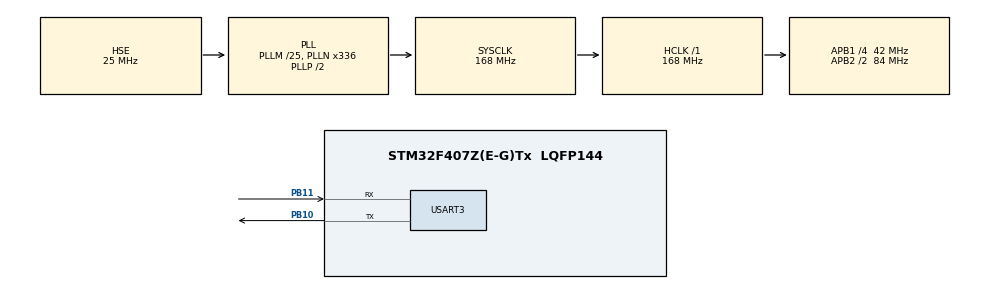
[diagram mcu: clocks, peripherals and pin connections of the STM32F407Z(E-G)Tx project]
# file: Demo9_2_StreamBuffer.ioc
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FREERTOS.Tasks01=Task_Show,24,256,AppTask_Show,Default,NULL,Dynamic,NULL,NULL
FREERTOS.configUSE_NEWLIB_REENTRANT=1
Mcu.Family=STM32F4
Mcu.Name=STM32F407Z(E-G)Tx
Mcu.Package=LQFP144
NVIC.PriorityGroup=NVIC_PRIORITYGROUP_4
NVIC.RTC_WKUP_IRQn=true\:5\:0\:false\:false\:true\:true\:true\:true\:true
NVIC.TIM6_DAC_IRQn=true\:0\:0\:true\:false\:true\:false\:false\:true\:true
NVIC.TimeBase=TIM6_DAC_IRQn
NVIC.TimeBaseIP=TIM6
PA13.Mode=Serial_Wire
PA13.Signal=SYS_JTMS-SWDIO
PA14.Mode=Serial_Wire
PA14.Signal=SYS_JTCK-SWCLK
PB10.Mode=Asynchronous
PB10.Signal=USART3_TX
PB11.Mode=Asynchronous
PB11.Signal=USART3_RX
PC14-OSC32_IN.Mode=LSE-External-Oscillator
PC14-OSC32_IN.Signal=RCC_OSC32_IN
PC15-OSC32_OUT.Mode=LSE-External-Oscillator
PC15-OSC32_OUT.Signal=RCC_OSC32_OUT
PH0-OSC_IN.Mode=HSE-External-Oscillator
PH0-OSC_IN.Signal=RCC_OSC_IN
PH1-OSC_OUT.Mode=HSE-External-Oscillator
PH1-OSC_OUT.Signal=RCC_OSC_OUT
ProjectManager.HeapSize=0x200
ProjectManager.StackSize=0x400
ProjectManager.TargetToolchain=STM32CubeIDE
RCC.48MHZClocksFreq_Value=84000000
RCC.AHBFreq_Value=168000000
RCC.APB1CLKDivider=RCC_HCLK_DIV4
RCC.APB1Freq_Value=42000000
RCC.APB1TimFreq_Value=84000000
RCC.APB2CLKDivider=RCC_HCLK_DIV2
RCC.APB2Freq_Value=84000000
RCC.APB2TimFreq_Value=168000000
RCC.CortexFreq_Value=168000000
RCC.HCLKFreq_Value=168000000
RCC.HSE_VALUE=25000000
RCC.HSI_VALUE=16000000
RCC.PLLM=25
RCC.PLLN=336
RCC.PLLSourceVirtual=RCC_PLLSOURCE_HSE
RCC.SYSCLKFreq_VALUE=168000000
RCC.SYSCLKSource=RCC_SYSCLKSOURCE_PLLCLK
RCC.VCOOutputFreq_Value=336000000
RTC.Date=24
RTC.Format=RTC_FORMAT_BIN
RTC.Hours=11
RTC.Minutes=45
RTC.Month=RTC_MONTH_MAY
RTC.Seconds=15
RTC.WakeUpClock=RTC_WAKEUPCLOCK_CK_SPRE_16BITS
RTC.WeekDay=RTC_WEEKDAY_SATURDAY
RTC.Year=25
USART3.VirtualMode=VM_ASYNC
VP_FREERTOS_VS_CMSIS_V2.Mode=CMSIS_V2
VP_RTC_VS_RTC_Activate.Mode=RTC_Enabled
VP_RTC_VS_RTC_Calendar.Mode=RTC_Calendar
VP_RTC_VS_RTC_WakeUp_intern.Mode=WakeUp
VP_SYS_VS_tim6.Mode=TIM6
board=custom

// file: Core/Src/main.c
/* USER CODE BEGIN Header */
/**
  ******************************************************************************
  * @file           : main.c
  * @brief          : Main program body
  ******************************************************************************
  * @attention
  *
  * Copyright (c) 2025 STMicroelectronics.
  * All rights reserved.
  *
  * This software is licensed under terms that can be found in the LICENSE file
  * in the root directory of this software component.
  * If no LICENSE file comes with this software, it is provided AS-IS.
  *
  ******************************************************************************
  */
/* USER CODE END Header */
#include "main.h"
#include "cmsis_os.h"
#include "rtc.h"
#include "usart.h"
#include "gpio.h"

void SystemClock_Config(void);
void MX_FREERTOS_Init(void);

int main(void)
{

  /* MCU Configuration--------------------------------------------------------*/

  /* Reset of all peripherals, Initializes the Flash interface and the Systick. */
  HAL_Init();

  /* Configure the system clock */
  SystemClock_Config();

  /* Initialize all configured peripherals */
  MX_GPIO_Init();
  MX_RTC_Init();
  MX_USART3_UART_Init();
  /* USER CODE BEGIN 2 */
  //Start Menu
  uint8_t startstr[] = "Demo9_2:Using Message Buffer.\r\n\r\n";
  HAL_UART_Transmit(&huart3,startstr,sizeof(startstr),0xFFFF);
  /* USER CODE END 2 */

  /* Init scheduler */
  osKernelInitialize();

  /* Call init function for freertos objects (in cmsis_os2.c) */
  MX_FREERTOS_Init();

  /* Start scheduler */
  osKernelStart();

  /* We should never get here as control is now taken by the scheduler */

  /* Infinite loop */
  while (1)
  {

  }
}

void SystemClock_Config(void)
{
  RCC_OscInitTypeDef RCC_OscInitStruct = {0};
  RCC_ClkInitTypeDef RCC_ClkInitStruct = {0};

  /** Configure the main internal regulator output voltage
  */
  __HAL_RCC_PWR_CLK_ENABLE();
  __HAL_PWR_VOLTAGESCALING_CONFIG(PWR_REGULATOR_VOLTAGE_SCALE1);

  /** Initializes the RCC Oscillators according to the specified parameters
  * in the RCC_OscInitTypeDef structure.
  */
  RCC_OscInitStruct.OscillatorType = RCC_OSCILLATORTYPE_LSI|RCC_OSCILLATORTYPE_HSE;
  RCC_OscInitStruct.HSEState = RCC_HSE_ON;
  RCC_OscInitStruct.LSIState = RCC_LSI_ON;
  RCC_OscInitStruct.PLL.PLLState = RCC_PLL_ON;
  RCC_OscInitStruct.PLL.PLLSource = RCC_PLLSOURCE_HSE;
  RCC_OscInitStruct.PLL.PLLM = 25;
  RCC_OscInitStruct.PLL.PLLN = 336;
  RCC_OscInitStruct.PLL.PLLP = RCC_PLLP_DIV2;
  RCC_OscInitStruct.PLL.PLLQ = 4;
  if (HAL_RCC_OscConfig(&RCC_OscInitStruct) != HAL_OK)
  {
    Error_Handler();
  }

  /** Initializes the CPU, AHB and APB buses clocks
  */
  RCC_ClkInitStruct.ClockType = RCC_CLOCKTYPE_HCLK|RCC_CLOCKTYPE_SYSCLK
                              |RCC_CLOCKTYPE_PCLK1|RCC_CLOCKTYPE_PCLK2;
  RCC_ClkInitStruct.SYSCLKSource = RCC_SYSCLKSOURCE_PLLCLK;
  RCC_ClkInitStruct.AHBCLKDivider = RCC_SYSCLK_DIV1;
  RCC_ClkInitStruct.APB1CLKDivider = RCC_HCLK_DIV4;
  RCC_ClkInitStruct.APB2CLKDivider = RCC_HCLK_DIV2;

  if (HAL_RCC_ClockConfig(&RCC_ClkInitStruct, FLASH_LATENCY_5) != HAL_OK)
  {
    Error_Handler();
  }
}

void HAL_TIM_PeriodElapsedCallback(TIM_HandleTypeDef *htim)
{
  if (htim->Instance == TIM6)
  {
    HAL_IncTick();
  }
}

void Error_Handler(void)
{
  __disable_irq();
  while (1)
  {
  }
}

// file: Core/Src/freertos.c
/* USER CODE BEGIN Header */
/**
  ******************************************************************************
  * File Name          : freertos.c
  * Description        : Code for freertos applications
  ******************************************************************************
  * @attention
  *
  * Copyright (c) 2025 STMicroelectronics.
  * All rights reserved.
  *
  * This software is licensed under terms that can be found in the LICENSE file
  * in the root directory of this software component.
  * If no LICENSE file comes with this software, it is provided AS-IS.
  *
  ******************************************************************************
  */
/* USER CODE END Header */

#include "FreeRTOS.h"
#include "task.h"
#include "main.h"
#include "cmsis_os.h"

/* USER CODE BEGIN Includes */
#include "message_buffer.h"
#include "usart.h"
#include <stdio.h>		//用到函数sprintf()
#include <string.h>		//用到函数strlen()
/* USER CODE END Includes */

/* USER CODE BEGIN PD */
#define	MSG_BUFFER_LEN	50			//消息缓存区长度，单位：字节
#define	MSG_MAX_LEN			20			//消息最大长度，单位：字节
/* USER CODE END PD */

/* USER CODE BEGIN Variables */
MessageBufferHandle_t  msgBuffer;		//消息缓存区句柄变量
/* USER CODE END Variables */
/* Definitions for Task_Show */
osThreadId_t Task_ShowHandle;
const osThreadAttr_t Task_Show_attributes = {
  .name = "Task_Show",
  .stack_size = 256 * 4,
  .priority = (osPriority_t) osPriorityNormal,
};

void AppTask_Show(void *argument);

void MX_FREERTOS_Init(void); /* (MISRA C 2004 rule 8.1) */

void MX_FREERTOS_Init(void) {

  /* Create the thread(s) */
  /* creation of Task_Show */
  Task_ShowHandle = osThreadNew(AppTask_Show, NULL, &Task_Show_attributes);

  /* USER CODE BEGIN RTOS_THREADS */
  /* add threads, ... */
  msgBuffer=xMessageBufferCreate(MSG_BUFFER_LEN);		//创建消息缓存区
  /* USER CODE END RTOS_THREADS */

}

void AppTask_Show(void *argument)
{
	/* USER CODE BEGIN AppTask_Show */
	/* Infinite loop */
	uint8_t dtArray[MSG_MAX_LEN];									//读出的数据临时保存数组
	for(;;)
	{
		uint16_t realCnt=xMessageBufferReceive(msgBuffer, dtArray,
				MSG_MAX_LEN, portMAX_DELAY);					//读取消息
		printf("Read message bytes   : %d\r\n", realCnt);		//实际读出字节数
		printf("message string Read  : %s\r\n", dtArray);		//显示读出的消息字符串
	}
	/* USER CODE END AppTask_Show */
}

/* USER CODE BEGIN Application */
void HAL_RTCEx_WakeUpTimerEventCallback(RTC_HandleTypeDef *hrtc)
{
	RTC_TimeTypeDef sTime;
	RTC_DateTypeDef sDate;
	if (HAL_RTC_GetTime(hrtc, &sTime,  RTC_FORMAT_BIN) != HAL_OK)
		return;
	if (HAL_RTC_GetDate(hrtc, &sDate,  RTC_FORMAT_BIN) !=HAL_OK)
		return;

	char dtArray[MSG_MAX_LEN];   								//存储消息的数组， MSG_MAX_LEN=20
	if ((sTime.Seconds % 2)==0)  									//分奇偶秒，发送不同长度的消息字符串
		siprintf(dtArray,"Seconds = %u\r\n",sTime.Seconds);	//转换为字符串,自动加'\0'
		//sprintf(dtArray,"Seconds = %u\r\n",sTime.Seconds);
	else
		//siprintf(dtArray,"Minute = %u\r\n",sTime.Minutes);		//转换为字符串,自动加'\0'
		sprintf(dtArray,"Minute = %u\r\n",sTime.Minutes);
	uint8_t bytesCount=strlen(dtArray);							//字符串长度，不带最后的结束符

	BaseType_t  highTaskWoken=pdFALSE;
	if (msgBuffer != NULL)
	{
		uint16_t  realCnt=xMessageBufferSendFromISR(msgBuffer,
				dtArray, bytesCount+1, &highTaskWoken);  // bytesCount+1，带结束符'\0'

		printf("Write bytes=   %d\r\n", realCnt);				//实际写入消息长度
		portYIELD_FROM_ISR(highTaskWoken);					//申请进行一次任务调度
	}
}

int __io_putchar(int ch)
{
	HAL_UART_Transmit(&huart3,(uint8_t*)&ch,1,0xFFFF);
	return ch;
}
/* USER CODE END Application */
